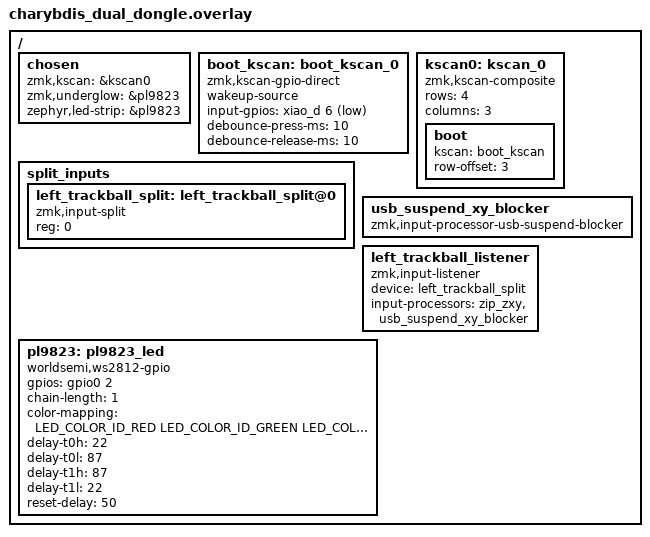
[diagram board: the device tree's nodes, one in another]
#include "charybdis_dual.dtsi"

#include <zephyr/dt-bindings/gpio/gpio.h>
#include <zephyr/dt-bindings/led/led.h>
#include <input/processors/xyz.dtsi>


/ {
    chosen {
        zmk,kscan = &kscan0;

        zmk,underglow = &pl9823;
        zephyr,led-strip = &pl9823;
    };


    /*
     * ========================================================
     * ドングル専用BOOTボタン
     *
     * D6 ---- push button ---- GND
     * ========================================================
     */

    boot_kscan: boot_kscan_0 {
        compatible = "zmk,kscan-gpio-direct";
        wakeup-source;

        input-gpios =
            <&xiao_d 6 (GPIO_ACTIVE_LOW | GPIO_PULL_UP)>;

        debounce-press-ms = <10>;
        debounce-release-ms = <10>;
    };


    /*
     * BOOTボタンをrow 3へ移動。
     *
     * dongleはcol-offset=0なので、
     * RC(3,0) → keymapのBOOT position 12
     */
    kscan0: kscan_0 {
        compatible = "zmk,kscan-composite";

        rows = <4>;
        columns = <3>;

        boot {
            kscan = <&boot_kscan>;
            row-offset = <3>;
        };
    };


    /*
     * ========================================================
     * 左トラックボール受信
     * ========================================================
     */

    split_inputs {
        #address-cells = <1>;
        #size-cells = <0>;

        left_trackball_split: left_trackball_split@0 {
            compatible = "zmk,input-split";
            reg = <0>;
        };
    };


    usb_suspend_xy_blocker: usb_suspend_xy_blocker {
        compatible =
            "zmk,input-processor-usb-suspend-blocker";

        #input-processor-cells = <0>;
    };


    left_trackball_listener: left_trackball_listener {
        compatible = "zmk,input-listener";
        device = <&left_trackball_split>;

        input-processors =
            <&zip_zxy>,
            <&usb_suspend_xy_blocker>;
    };


    /*
     * ========================================================
     * 外付け PL9823-F5
     *
     * XIAO D0 = P0.02
     * ========================================================
     */

    pl9823: pl9823_led {
        compatible = "worldsemi,ws2812-gpio";

        gpios = <&gpio0 2 GPIO_ACTIVE_HIGH>;

        chain-length = <1>;

        color-mapping = <
            LED_COLOR_ID_RED
            LED_COLOR_ID_GREEN
            LED_COLOR_ID_BLUE
        >;

        delay-t0h = <22>;
        delay-t0l = <87>;
        delay-t1h = <87>;
        delay-t1l = <22>;

        reset-delay = <50>;
    };
};
